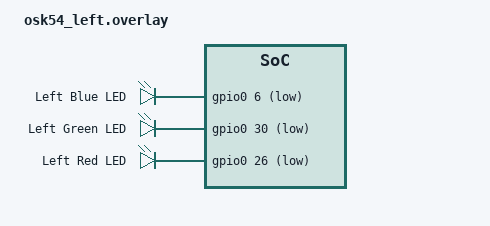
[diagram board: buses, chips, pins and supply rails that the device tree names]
// This file was generated from a template. Edit it to match your keyboard.
// See https://zmk.dev/docs/development/hardware-integration/new-shield for more
// instructions.

#include "osk54.dtsi"

&kscan {
    // Replace these comments with the GPIO pins in the matrix for the left side.
    // See https://zmk.dev/docs/development/hardware-integration/new-shield#shield-overlays
    //col-gpios
    //    = <&xiao_d 0 GPIO_ACTIVE_HIGH>
    //    , <&xiao_d 0 GPIO_ACTIVE_HIGH>
    //    ;
    col-gpios
        = <&xiao_d 0 GPIO_ACTIVE_HIGH>   /* col 0 — extra pinky */
        , <&xiao_d 1 GPIO_ACTIVE_HIGH>   /* col 1 — pinky       */
        , <&xiao_d 2 GPIO_ACTIVE_HIGH>   /* col 2 — ring        */
        , <&xiao_d 3 GPIO_ACTIVE_HIGH>   /* col 3 — middle      */
        , <&xiao_d 4 GPIO_ACTIVE_HIGH>   /* col 4 — index       */
        , <&xiao_d 5 GPIO_ACTIVE_HIGH>   /* col 5 — inner       */
        ;
};

/ {
    leds {
        compatible = "gpio-leds";
        left_blue_led: led_0 {
            gpios = <&gpio0 6 GPIO_ACTIVE_LOW>;
            label = "Left Blue LED";
        };
        left_green_led: led_1 {
            gpios = <&gpio0 30 GPIO_ACTIVE_LOW>;
            label = "Left Green LED";
        };
        left_red_led: led_2 {
            gpios = <&gpio0 26 GPIO_ACTIVE_LOW>;
            label = "Left Red LED";
        };
    };
}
